# ipro6s register map
Vendor: intelpro; Series: IPRO6S
CPU: ipro6s, little endian
Registers are 32-bit, read-write, reset 0x0 unless marked. A register's access mark holds for its fields unless they carry their own. Offsets are from the block's base; [hi:lo] are bit positions.

## D2XA
Base 0x30018000
Same registers: D2XB 0x30019000
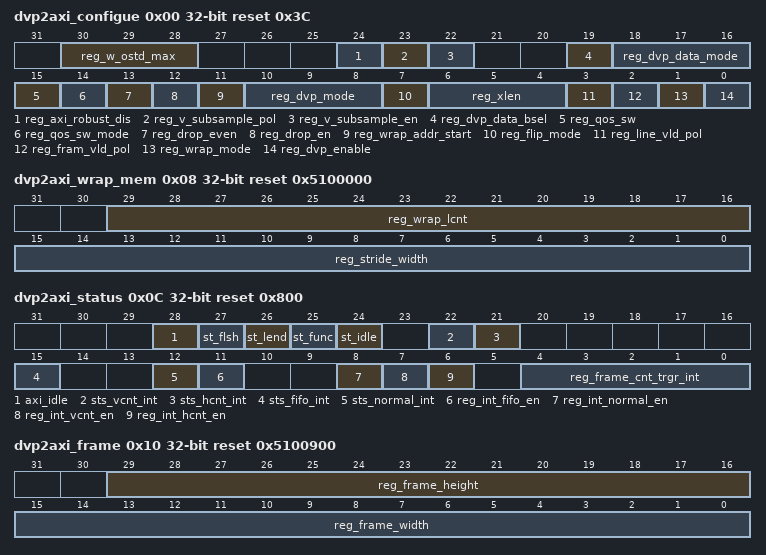
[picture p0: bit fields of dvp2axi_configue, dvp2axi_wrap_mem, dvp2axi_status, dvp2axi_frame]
0x00 dvp2axi_configue reset 0x3C
  [30:28] reg_w_ostd_max — Reserved for HW use
  [24] reg_axi_robust_dis — Reserved for HW use
  [23] reg_v_subsample_pol — DVP2BUS vertical sub-sampling polarity 1'b0: Odd lines are masked 1'b1: Even lines are masked
  [22] reg_v_subsample_en — DVP2BUS vertical sub-sampling enable
  [19] reg_dvp_data_bsel — Byte select signal for DVP 8-bit mode, don't care if reg_dvp_data_8bit is disabled 1'b0: Select the lower byte of pix_data 1'b1: Select the upper byte of pix_data
  [18:16] reg_dvp_data_mode — DVP 8-bit mode enable 3'd0: DVP pix_data is 16-bit wide 3'd1: DVP pix_data is 24-bit mode 3'd2: DVP pix_data is 24-comp-16-bit mode 3'd3: DVP pix_data is 24-exp-32-bit mode 3'd4: DVP pix_data is 8-bit wide 3'd5: DVP pix_data is 12-bit wide Others - Reserved
  [15] reg_qos_sw — AXI Qos software mode value
  [14] reg_qos_sw_mode — AXI QoS software mode enable
  [13] reg_drop_even — Only effect when reg_drop_en=1 : 1'b1 : Drop all even bytes 1'b0 : Drop all odd bytes
  [12] reg_drop_en — Drop mode Enable
  [11] reg_wrap_addr_start — 1'b1 - Force frame start address to reg_addr_start(0x4) 1'b0 - Do not force，Frame start address will be calculated from last frame address end
  [10:8] reg_dvp_mode — Image senosr mode selection: 3'd0-Vsync&Hsync 3'd1-Vsync|Hsync 3'd2-Vsync 3'd3-Hsync
  [7] reg_flip_mode — DVP2AXI memroy flip mode enable
  [6:4] reg_xlen — burst length setting 3'd0 - Single / 3'd1 - INCR4 / 3'd2 - INCR8 3'd3 - INCR16 / 3'd5 - INCR32 / 3'd6 - INCR64
  [3] reg_line_vld_pol — Image sensor line valid polarity, 1'b0 - Activel low, 1'b1 - Active high
  [2] reg_fram_vld_pol — Image sensor frame valid polarity, 1'b0 - Activel low, 1'b1 - Active high
  [1] reg_wrap_mode — DVP2AXI memroy wrap mode enable
  [0] reg_dvp_enable — module enable
0x04 dvp2axi_addr_start reset 0x80000000
  [31:0] reg_addr_start — AXI start address
0x08 dvp2axi_wrap_mem reset 0x5100000
  [29:16] reg_wrap_lcnt — Wrap mode memory line count(unit - line)
  [15:0] reg_stride_width — Frame stride width / 8 (unit - byte)
0x0C dvp2axi_status reset 0x800 (reset mask 0x9DF)
  [28] axi_idle ro — DVP2BUS AHB idle status
  [27] st_flsh ro — Module state in flush
  [26] st_lend ro — Module state in frame end
  [25] st_func ro — Module state in function
  [24] st_idle ro — Module state in idle
  [22] sts_vcnt_int ro — Vsync valid line count non-match interrupt status
  [21] sts_hcnt_int ro — Hsync valid pixel count non-match interrupt status
  [15] sts_fifo_int ro — FIFO OverWrite interrupt status
  [12] sts_normal_int ro — Normal Write interrupt status
  [11] reg_int_fifo_en — FIFO OverWrite interrupt enable
  [8] reg_int_normal_en — Normal Write interrupt enable
  [7] reg_int_vcnt_en — Vsync valid line count match interrupt enable
  [6] reg_int_hcnt_en — Hsync valid pixel count match interrupt enable
  [4:0] reg_frame_cnt_trgr_int — Frame to issue interrupt at SW Mode
0x10 dvp2axi_frame reset 0x5100900
  [29:16] reg_frame_height — Frame hight (unit - line)
  [15:0] reg_frame_width — Frame real write width / 8 (unit - byte)
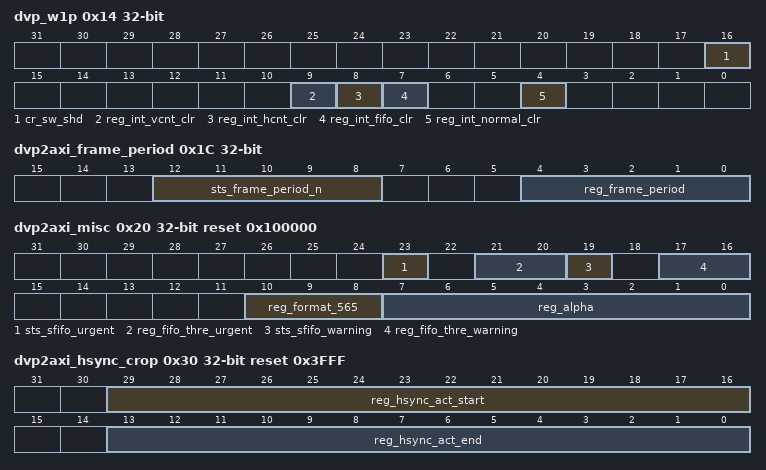
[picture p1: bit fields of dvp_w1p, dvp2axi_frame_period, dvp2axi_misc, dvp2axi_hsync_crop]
0x14 dvp_w1p
  [16] cr_sw_shd wo — Software shadow enable
  [9] reg_int_vcnt_clr wo — Interrupt clear
  [8] reg_int_hcnt_clr wo — Interrupt clear
  [7] reg_int_fifo_clr wo — Interrupt clear
  [4] reg_int_normal_clr wo — Interrupt clear
0x18 dvp2axi_frame_vld reset 0xFFFFFFFF
  [31:0] reg_frame_n_vld — Bitwise frame valid in period
0x1C dvp2axi_frame_period (reset mask 0x1F)
  [12:8] sts_frame_period_n ro — Frame period cnt status
  [4:0] reg_frame_period — Frame period cnt. (EX. Set this register 0, the period is 1)
0x20 dvp2axi_misc reset 0x100000 (reset mask 0x3307FF)
  [23] sts_sfifo_urgent ro — FIFO Urgent status
  [21:20] reg_fifo_thre_urgent — FIFO urgent signal threshold setting 2'd0 : 1/4 FIFO Full 2'd1 : 1/2 FIFO Full 2'd2 : 3/4 FIFO Full
  [19] sts_sfifo_warning ro — FIFO Warning status
  [17:16] reg_fifo_thre_warning — FIFO warning signal threshold setting 2'd0 : 1/4 FIFO Full 2'd1 : 1/2 FIFO Full 2'd2 : 3/4 FIFO Full
  [10:8] reg_format_565 — Only work when reg_dvp_data_mode=2 (24-comp-16-bit mode) 3'd0: B2(5)B1(6)B0(5) 3'd1: B1(5)B2(6)B0(5) 3'd2: B2(5)B0(6)B1(5) 3'd3: B0(5)B2(6)B1(5) 3'd4: B1(5)B0(6)B2(5) 3'd5: B0(5)B1(6)B2(5)
  [7:0] reg_alpha — Only work when "reg_dvp_data_mode==2'd3(DVP pix_data is 24-exp-32-bit mode)" The value of [31:24]
0x30 dvp2axi_hsync_crop reset 0x3FFF
  [29:16] reg_hsync_act_start — Valid hsync start cnt(unit-pixel)
  [13:0] reg_hsync_act_end — Valid hsync end cnt(unit-pixel)
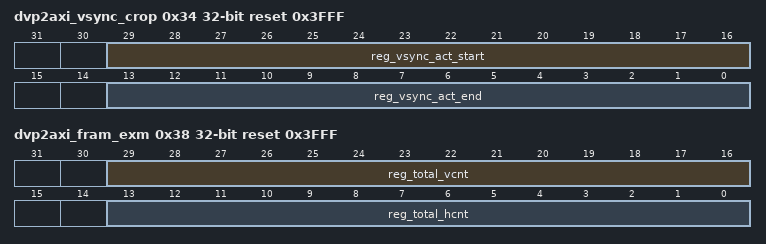
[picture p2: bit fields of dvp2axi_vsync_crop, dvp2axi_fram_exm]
0x34 dvp2axi_vsync_crop reset 0x3FFF
  [29:16] reg_vsync_act_start — Valid vsync start cnt(unit-pixel)
  [13:0] reg_vsync_act_end — Valid vsync end cnt(unit-pixel)
0x38 dvp2axi_fram_exm reset 0x3FFF
  [29:16] reg_total_vcnt — Total valid line count in a frame(unit-pixel)
  [13:0] reg_total_hcnt — Total valid pix count in a line(unit-pixel)
0xFC dvp_dummy_reg reset 0xF0 (reset mask 0xFF)
